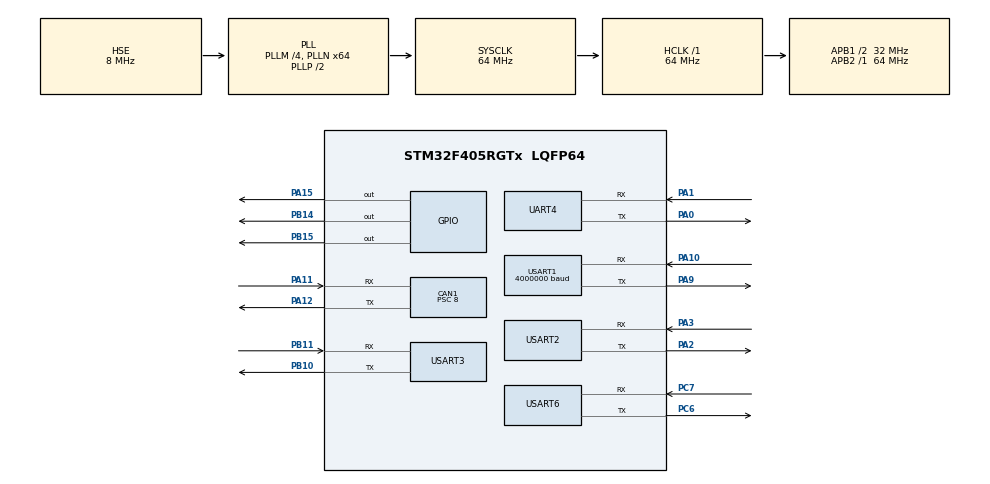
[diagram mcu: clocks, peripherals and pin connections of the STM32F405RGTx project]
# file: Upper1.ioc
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CAN1.BS1=CAN_BS1_2TQ
CAN1.CalculateBaudRate=1000000
CAN1.CalculateTimeBit=1000
CAN1.CalculateTimeQuantum=250.0
CAN1.Prescaler=8
FREERTOS.Tasks01=defaultTask,24,128,StartDefaultTask,As weak,NULL,Dynamic,NULL,NULL;Task_Hit,8,128,task_hit,As external,NULL,Dynamic,NULL,NULL;Test_LED,8,128,test_led_task,As external,NULL,Dynamic,NULL,NULL;Task_Bow_Slew,8,128,task_bow_slew,As external,NULL,Dynamic,NULL,NULL;Task_Main,8,128,task_main,As external,NULL,Dynamic,NULL,NULL
Mcu.Family=STM32F4
Mcu.Name=STM32F405RGTx
Mcu.Package=LQFP64
NVIC.CAN1_RX0_IRQn=true\:5\:0\:false\:false\:true\:true\:true\:true\:true
NVIC.CAN1_RX1_IRQn=true\:5\:0\:false\:false\:true\:true\:true\:true\:true
NVIC.PriorityGroup=NVIC_PRIORITYGROUP_4
NVIC.TIM1_BRK_TIM9_IRQn=true\:5\:0\:false\:false\:true\:false\:false\:true\:true
NVIC.TIM2_IRQn=true\:5\:0\:false\:false\:true\:true\:true\:true\:true
NVIC.TimeBase=TIM1_BRK_TIM9_IRQn
NVIC.TimeBaseIP=TIM9
NVIC.USART2_IRQn=true\:5\:0\:false\:false\:true\:true\:true\:true\:true
NVIC.USART6_IRQn=true\:5\:0\:false\:false\:true\:true\:true\:true\:true
PA0-WKUP.Mode=Asynchronous
PA0-WKUP.Signal=UART4_TX
PA1.Mode=Asynchronous
PA1.Signal=UART4_RX
PA10.Mode=Asynchronous
PA10.Signal=USART1_RX
PA11.Mode=CAN_Activate
PA11.Signal=CAN1_RX
PA12.Mode=CAN_Activate
PA12.Signal=CAN1_TX
PA13.Mode=Serial_Wire
PA13.Signal=SYS_JTMS-SWDIO
PA14.Mode=Serial_Wire
PA14.Signal=SYS_JTCK-SWCLK
PA15.Signal=GPIO_Output
PA2.Mode=Asynchronous
PA2.Signal=USART2_TX
PA3.Mode=Asynchronous
PA3.Signal=USART2_RX
PA9.Mode=Asynchronous
PA9.Signal=USART1_TX
PB10.Mode=Asynchronous
PB10.Signal=USART3_TX
PB11.Mode=Asynchronous
PB11.Signal=USART3_RX
PB14.Signal=GPIO_Output
PB15.Signal=GPIO_Output
PC6.Mode=Asynchronous
PC6.Signal=USART6_TX
PC7.Mode=Asynchronous
PC7.Signal=USART6_RX
PH0-OSC_IN.Mode=HSE-External-Oscillator
PH0-OSC_IN.Signal=RCC_OSC_IN
PH1-OSC_OUT.Mode=HSE-External-Oscillator
PH1-OSC_OUT.Signal=RCC_OSC_OUT
ProjectManager.HeapSize=0x200
ProjectManager.StackSize=0x400
ProjectManager.TargetToolchain=MDK-ARM V5.32
RCC.48MHZClocksFreq_Value=32000000
RCC.AHBFreq_Value=64000000
RCC.APB1CLKDivider=RCC_HCLK_DIV2
RCC.APB1Freq_Value=32000000
RCC.APB1TimFreq_Value=64000000
RCC.APB2Freq_Value=64000000
RCC.APB2TimFreq_Value=64000000
RCC.CortexFreq_Value=64000000
RCC.HCLKFreq_Value=64000000
RCC.HSE_VALUE=8000000
RCC.HSI_VALUE=16000000
RCC.LSE_VALUE=32768
RCC.PLLM=4
RCC.PLLN=64
RCC.PLLSourceVirtual=RCC_PLLSOURCE_HSE
RCC.SYSCLKFreq_VALUE=64000000
RCC.SYSCLKSource=RCC_SYSCLKSOURCE_PLLCLK
RCC.VCOOutputFreq_Value=128000000
TIM2.AutoReloadPreload=TIM_AUTORELOAD_PRELOAD_ENABLE
TIM2.Period=999
TIM2.Prescaler=167
UART4.VirtualMode=Asynchronous
USART1.BaudRate=4000000
USART1.VirtualMode=VM_ASYNC
USART2.VirtualMode=VM_ASYNC
USART3.VirtualMode=VM_ASYNC
USART6.VirtualMode=VM_ASYNC
VP_FREERTOS_VS_CMSIS_V2.Mode=CMSIS_V2
VP_SYS_VS_tim9.Mode=TIM9
VP_TIM2_VS_ClockSourceINT.Mode=Internal
board=custom

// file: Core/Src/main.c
/* USER CODE BEGIN Header */
/**
  ******************************************************************************
  * @file           : main.c
  * @brief          : Main program body
  ******************************************************************************
  * @attention
  *
  * Copyright (c) 2025 STMicroelectronics.
  * All rights reserved.
  *
  * This software is licensed under terms that can be found in the LICENSE file
  * in the root directory of this software component.
  * If no LICENSE file comes with this software, it is provided AS-IS.
  *
  ******************************************************************************
  */
/* USER CODE END Header */
#include "main.h"
#include "cmsis_os.h"
#include "can.h"
#include "tim.h"
#include "usart.h"
#include "gpio.h"

void SystemClock_Config(void);
void MX_FREERTOS_Init(void);

/* USER CODE BEGIN 0 */
uint8_t data_uart_rec=0;
uint8_t my_jump_flag = 0;
uint8_t my_start_flag = false;
uint8_t dribble = 0;
bool my_lock_flag = true;

/* USER CODE END 0 */

int main(void)
{

  /* MCU Configuration--------------------------------------------------------*/

  /* Reset of all peripherals, Initializes the Flash interface and the Systick. */
  HAL_Init();

  /* Configure the system clock */
  SystemClock_Config();

  /* Initialize all configured peripherals */
  MX_GPIO_Init();
  MX_USART1_UART_Init();
  MX_UART4_Init();
  MX_USART2_UART_Init();
  MX_USART3_UART_Init();
  MX_TIM2_Init();
  MX_CAN1_Init();
  MX_USART6_UART_Init();
  /* USER CODE BEGIN 2 */
	char p[] = "aaaa";
	HAL_UART_Receive_IT(&huart2,&data_uart_rec,1);
//	HAL_GPIO_WritePin(GPIOA,GPIO_PIN_15,GPIO_PIN_SET);
//	HAL_GPIO_WritePin(GPIOB,GPIO_PIN_14,GPIO_PIN_SET);
//	HAL_GPIO_WritePin(GPIOB,GPIO_PIN_15,GPIO_PIN_SET);
	HAL_TIM_Base_Start_IT(&htim2);
	HAL_Delay(500);

  /* USER CODE END 2 */

  /* Init scheduler */
  osKernelInitialize();  /* Call init function for freertos objects (in cmsis_os2.c) */
  MX_FREERTOS_Init();

  /* Start scheduler */
  osKernelStart();

  /* We should never get here as control is now taken by the scheduler */

  /* Infinite loop */
  /* USER CODE BEGIN WHILE */
  while (1)
  {

//		modify_data(&cmd);

//    tx_res = HAL_UART_Transmit(&huart1, (uint8_t *)&cmd.motor_send_data, sizeof(cmd.motor_send_data), 1);
//
//    rx_res = HAL_UART_Receive(&huart1, (uint8_t *)&data.motor_recv_data, sizeof(data.motor_recv_data), 1);
//    if (rx_res == HAL_TIMEOUT)
//    {
//      data.timeout++;
//    }
//
//    extract_data(&data);
//		HAL_Delay(1);
    /* USER CODE END WHILE */

  }
}

void SystemClock_Config(void)
{
  RCC_OscInitTypeDef RCC_OscInitStruct = {0};
  RCC_ClkInitTypeDef RCC_ClkInitStruct = {0};

  /** Configure the main internal regulator output voltage
  */
  __HAL_RCC_PWR_CLK_ENABLE();
  __HAL_PWR_VOLTAGESCALING_CONFIG(PWR_REGULATOR_VOLTAGE_SCALE1);

  /** Initializes the RCC Oscillators according to the specified parameters
  * in the RCC_OscInitTypeDef structure.
  */
  RCC_OscInitStruct.OscillatorType = RCC_OSCILLATORTYPE_HSE;
  RCC_OscInitStruct.HSEState = RCC_HSE_ON;
  RCC_OscInitStruct.PLL.PLLState = RCC_PLL_ON;
  RCC_OscInitStruct.PLL.PLLSource = RCC_PLLSOURCE_HSE;
  RCC_OscInitStruct.PLL.PLLM = 4;
  RCC_OscInitStruct.PLL.PLLN = 64;
  RCC_OscInitStruct.PLL.PLLP = RCC_PLLP_DIV2;
  RCC_OscInitStruct.PLL.PLLQ = 4;
  if (HAL_RCC_OscConfig(&RCC_OscInitStruct) != HAL_OK)
  {
    Error_Handler();
  }

  /** Initializes the CPU, AHB and APB buses clocks
  */
  RCC_ClkInitStruct.ClockType = RCC_CLOCKTYPE_HCLK|RCC_CLOCKTYPE_SYSCLK
                              |RCC_CLOCKTYPE_PCLK1|RCC_CLOCKTYPE_PCLK2;
  RCC_ClkInitStruct.SYSCLKSource = RCC_SYSCLKSOURCE_PLLCLK;
  RCC_ClkInitStruct.AHBCLKDivider = RCC_SYSCLK_DIV1;
  RCC_ClkInitStruct.APB1CLKDivider = RCC_HCLK_DIV2;
  RCC_ClkInitStruct.APB2CLKDivider = RCC_HCLK_DIV1;

  if (HAL_RCC_ClockConfig(&RCC_ClkInitStruct, FLASH_LATENCY_2) != HAL_OK)
  {
    Error_Handler();
  }
}

void HAL_TIM_PeriodElapsedCallback(TIM_HandleTypeDef *htim)
{
  /* USER CODE BEGIN Callback 0 */
	if(htim->Instance == TIM2)
	{
//			_tim2_callback();

	}
  /* USER CODE END Callback 0 */
  if (htim->Instance == TIM9)
  {
    HAL_IncTick();
  }
}

void Error_Handler(void)
{
  __disable_irq();
  while (1)
  {
  }
}

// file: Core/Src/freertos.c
/* USER CODE BEGIN Header */
/**
  ******************************************************************************
  * File Name          : freertos.c
  * Description        : Code for freertos applications
  ******************************************************************************
  * @attention
  *
  * Copyright (c) 2025 STMicroelectronics.
  * All rights reserved.
  *
  * This software is licensed under terms that can be found in the LICENSE file
  * in the root directory of this software component.
  * If no LICENSE file comes with this software, it is provided AS-IS.
  *
  ******************************************************************************
  */
/* USER CODE END Header */

#include "FreeRTOS.h"
#include "task.h"
#include "main.h"
#include "cmsis_os.h"

/* Definitions for defaultTask */
osThreadId_t defaultTaskHandle;
const osThreadAttr_t defaultTask_attributes = {
  .name = "defaultTask",
  .stack_size = 128 * 4,
  .priority = (osPriority_t) osPriorityNormal,
};
/* Definitions for Task_Hit */
osThreadId_t Task_HitHandle;
const osThreadAttr_t Task_Hit_attributes = {
  .name = "Task_Hit",
  .stack_size = 128 * 4,
  .priority = (osPriority_t) osPriorityLow,
};
/* Definitions for Test_LED */
osThreadId_t Test_LEDHandle;
const osThreadAttr_t Test_LED_attributes = {
  .name = "Test_LED",
  .stack_size = 128 * 4,
  .priority = (osPriority_t) osPriorityLow,
};
/* Definitions for Task_Bow_Slew */
osThreadId_t Task_Bow_SlewHandle;
const osThreadAttr_t Task_Bow_Slew_attributes = {
  .name = "Task_Bow_Slew",
  .stack_size = 128 * 4,
  .priority = (osPriority_t) osPriorityLow,
};
/* Definitions for Task_Main */
osThreadId_t Task_MainHandle;
const osThreadAttr_t Task_Main_attributes = {
  .name = "Task_Main",
  .stack_size = 128 * 4,
  .priority = (osPriority_t) osPriorityLow,
};

void StartDefaultTask(void *argument);
extern void task_hit(void *argument);
extern void test_led_task(void *argument);
extern void task_bow_slew(void *argument);
extern void task_main(void *argument);

void MX_FREERTOS_Init(void); /* (MISRA C 2004 rule 8.1) */

void MX_FREERTOS_Init(void) {

  /* Create the thread(s) */
  /* creation of defaultTask */
  defaultTaskHandle = osThreadNew(StartDefaultTask, NULL, &defaultTask_attributes);

  /* creation of Task_Hit */
  Task_HitHandle = osThreadNew(task_hit, NULL, &Task_Hit_attributes);

  /* creation of Test_LED */
  Test_LEDHandle = osThreadNew(test_led_task, NULL, &Test_LED_attributes);

  /* creation of Task_Bow_Slew */
  Task_Bow_SlewHandle = osThreadNew(task_bow_slew, NULL, &Task_Bow_Slew_attributes);

  /* creation of Task_Main */
  Task_MainHandle = osThreadNew(task_main, NULL, &Task_Main_attributes);

}

__weak void StartDefaultTask(void *argument)
{
  for(;;)
  {
    osDelay(1);
  }
}
